# COMPUTE_CLUSTER0_CTL_CFG register map
Vendor: Texas Instruments
Peripheral module from a debugger description file (folder J7VCL).
Registers are 32-bit, read-write, reset 0x0 unless marked. A register's access mark holds for its fields unless they carry their own. Offsets are as the file gives them; lines under a group give offsets from that group; [hi:lo] are bit positions; {n}, {i} and the like mark numbered series; 'fields as' and 'values as' point back to an identical list; <NAME> marks a mode.

## COMPUTE_CLUSTER0_CTL_CFG (part 1 of 3)
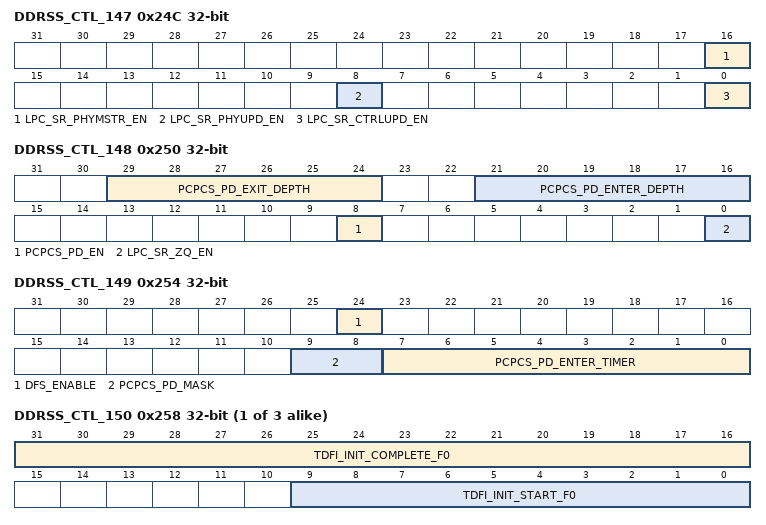
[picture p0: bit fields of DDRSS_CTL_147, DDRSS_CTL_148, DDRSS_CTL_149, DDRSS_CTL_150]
0x24C DDRSS_CTL_147
  [16] LPC_SR_PHYMSTR_EN — Enable LPC to execute a DFI PHY Master request on a self-refresh exit sequence.
  [8] LPC_SR_PHYUPD_EN — Enable LPC to execute a DFI PHY update on a self-refresh exit sequence.
  [0] LPC_SR_CTRLUPD_EN — Enable LPC to execute a DFI control update on a self-refresh exit sequence.
0x250 DDRSS_CTL_148
  [29:24] PCPCS_PD_EXIT_DEPTH — Defines the number of entries of the command queue that the PCPCS logic will consider for dynamic power-down exit decode.
  [21:16] PCPCS_PD_ENTER_DEPTH — Defines the number of entries of the command queue that the PCPCS logic will consider for dynamic power-down entry decode.
  [8] PCPCS_PD_EN — Enable dynamic PCPCS to allow chip selects to dynamically enter and exit power-down.
  [0] LPC_SR_ZQ_EN — Enable LPC to execute a ZQ calibration on a self-refresh exit sequence.
0x254 DDRSS_CTL_149
  [24] DFS_ENABLE — Enable hardware dynamic frequency scaling.
  [9:8] PCPCS_PD_MASK — Disables dynamic PCPCS power-down entry/exit for particular chip selects if the PCPCS_PD_EN parameter is set.
  [7:0] PCPCS_PD_ENTER_TIMER — Sets the delay used by dynamic PCPCS from when the decode logic determines that a chip select has no outstanding transactions to when the power-down entry command is issued.
{0x0+4i} DDRSS_CTL_{i} (i=150..152)
  [31:16] TDFI_INIT_COMPLETE_F{i-150} — Defines the DFI tINIT_COMPLETE timing parameter (in DFI clocks) for frequency copy {i-150}, the maximum cycles between a dfi_init_start de-assertion and a dfi_init_complete assertion from the PHY.
  [9:0] TDFI_INIT_START_F{i-150} — Defines the DFI tINIT_START timing parameter (in DFI clocks) for frequency copy {i-150}, the maximum number of cycles between a dfi_init_start assertion and a dfi_init_complete de-assertion from the PHY.
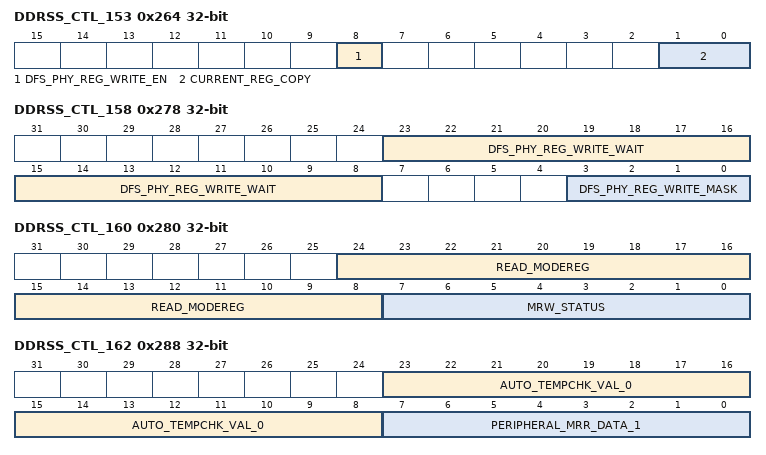
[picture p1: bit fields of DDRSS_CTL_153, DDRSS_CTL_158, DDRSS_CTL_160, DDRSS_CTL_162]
0x264 DDRSS_CTL_153 access per field
  [8] DFS_PHY_REG_WRITE_EN rw — Enable a register write to the PHY during a frequency change.
  [1:0] CURRENT_REG_COPY ro — Indicates the current copy of timing parameters that is in use by the controller.
0x268 DDRSS_CTL_154
  [31:0] DFS_PHY_REG_WRITE_ADDR — Register address which will be written during a frequency change.
{0x0+4i} DDRSS_CTL_{i} (i=155..157)
  [31:0] DFS_PHY_REG_WRITE_DATA_F{i-155} — Register data which will be written during a frequency change for frequency copy {i-155}.
0x278 DDRSS_CTL_158
  [23:8] DFS_PHY_REG_WRITE_WAIT — Defines the number of DFI PHY clocks that the controller will wait after issuing the register write to the PHY during a frequency change.
  [3:0] DFS_PHY_REG_WRITE_MASK — Register mask which will be written during a frequency change.
0x27C DDRSS_CTL_159
  [26:0] WRITE_MODEREG — Write memory mode register data to the DRAMs.
0x280 DDRSS_CTL_160 access per field
  [24:8] READ_MODEREG rw — Read the specified memory mode register from specified chip when start bit set.
  [7:0] MRW_STATUS ro — Write memory mode register status.
0x284 DDRSS_CTL_161 ro
  [31:0] PERIPHERAL_MRR_DATA_0 — Data and chip returned from memory mode register read requested by the READ_MODEREG parameter.
0x288 DDRSS_CTL_162 ro
  [23:8] AUTO_TEMPCHK_VAL_0 — MR4 data for all devices on chip 0 accessed by automatic MRR commands.
  [7:0] PERIPHERAL_MRR_DATA_1 — Data and chip returned from memory mode register read requested by the READ_MODEREG parameter.
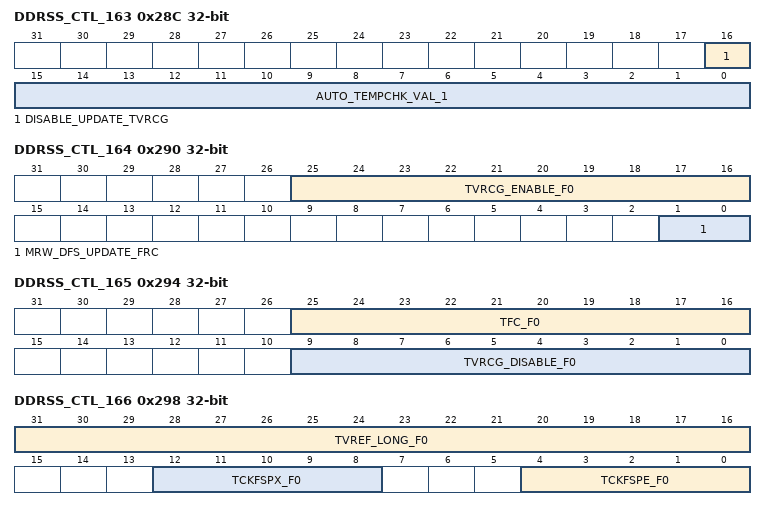
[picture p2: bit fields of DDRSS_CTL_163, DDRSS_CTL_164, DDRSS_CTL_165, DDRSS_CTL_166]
0x28C DDRSS_CTL_163 access per field
  [16] DISABLE_UPDATE_TVRCG rw — Bypass changing for TVRCG during a DFS operation.
  [15:0] AUTO_TEMPCHK_VAL_1 ro — MR4 data for all devices on chip 1 accessed by automatic MRR commands.
0x290 DDRSS_CTL_164
  [25:16] TVRCG_ENABLE_F0 — JEDEC TVRCG_ENABLE time.
  [1:0] MRW_DFS_UPDATE_FRC — Defines the frequency register set to use when doing a software MRW with WRITE_MODEREG bit (26).
0x294 DDRSS_CTL_165
  [25:16] TFC_F0 — JEDEC TFC, the frequency set point switching time.
  [9:0] TVRCG_DISABLE_F0 — JEDEC TVRCG_DISABLE time.
0x298 DDRSS_CTL_166
  [31:16] TVREF_LONG_F0 — JEDEC TVREF, design will always use the long value.
  [12:8] TCKFSPX_F0 — JEDEC TCKFSPX, the valid clock requirement before 1st valid command after FSP change.
  [4:0] TCKFSPE_F0 — JEDEC TCKFSPE, the valid clock requirement after entering SDP change.
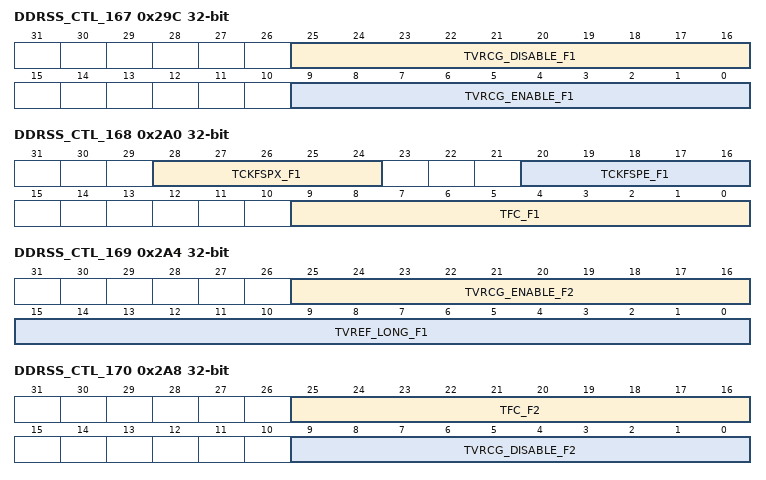
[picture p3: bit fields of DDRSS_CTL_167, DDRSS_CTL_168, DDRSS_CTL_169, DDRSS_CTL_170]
0x29C DDRSS_CTL_167
  [25:16] TVRCG_DISABLE_F1 — JEDEC TVRCG_DISABLE time.
  [9:0] TVRCG_ENABLE_F1 — JEDEC TVRCG_ENABLE time.
0x2A0 DDRSS_CTL_168
  [28:24] TCKFSPX_F1 — JEDEC TCKFSPX, the valid clock requirement before 1st valid command after FSP change.
  [20:16] TCKFSPE_F1 — JEDEC TCKFSPE, the valid clock requirement after entering SDP change.
  [9:0] TFC_F1 — JEDEC TFC, the frequency set point switching time.
0x2A4 DDRSS_CTL_169
  [25:16] TVRCG_ENABLE_F2 — JEDEC TVRCG_ENABLE time.
  [15:0] TVREF_LONG_F1 — JEDEC TVREF, design will always use the long value.
0x2A8 DDRSS_CTL_170
  [25:16] TFC_F2 — JEDEC TFC, the frequency set point switching time.
  [9:0] TVRCG_DISABLE_F2 — JEDEC TVRCG_DISABLE time.
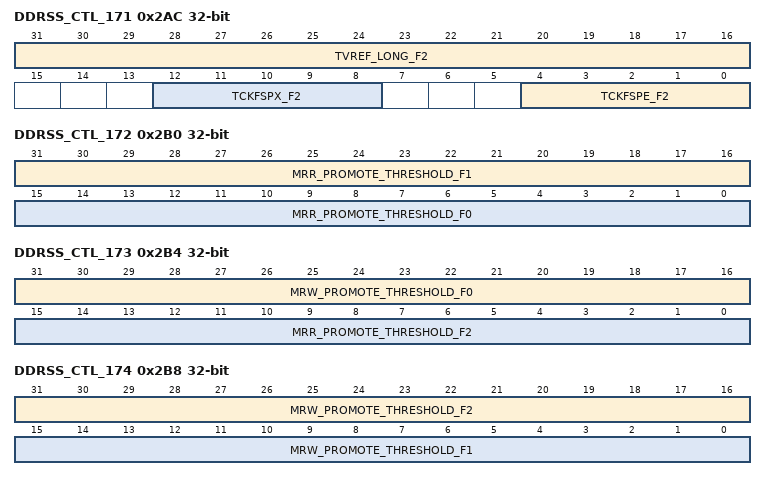
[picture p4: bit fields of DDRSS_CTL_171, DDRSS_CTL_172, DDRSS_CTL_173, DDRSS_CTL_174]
0x2AC DDRSS_CTL_171
  [31:16] TVREF_LONG_F2 — JEDEC TVREF, design will always use the long value.
  [12:8] TCKFSPX_F2 — JEDEC TCKFSPX, the valid clock requirement before 1st valid command after FSP change.
  [4:0] TCKFSPE_F2 — JEDEC TCKFSPE, the valid clock requirement after entering SDP change.
0x2B0 DDRSS_CTL_172
  [31:16] MRR_PROMOTE_THRESHOLD_F1 — MRR promotion number of long counts until the high priority request is asserted for frequency copy 1.
  [15:0] MRR_PROMOTE_THRESHOLD_F0 — MRR promotion number of long counts until the high priority request is asserted for frequency copy 0.
0x2B4 DDRSS_CTL_173
  [31:16] MRW_PROMOTE_THRESHOLD_F0 — MRW promotion number of long counts until the high priority request is asserted for frequency copy 0.
  [15:0] MRR_PROMOTE_THRESHOLD_F2 — MRR promotion number of long counts until the high priority request is asserted for frequency copy 2.
0x2B8 DDRSS_CTL_174
  [31:16] MRW_PROMOTE_THRESHOLD_F2 — MRW promotion number of long counts until the high priority request is asserted for frequency copy 2.
  [15:0] MRW_PROMOTE_THRESHOLD_F1 — MRW promotion number of long counts until the high priority request is asserted for frequency copy 1.
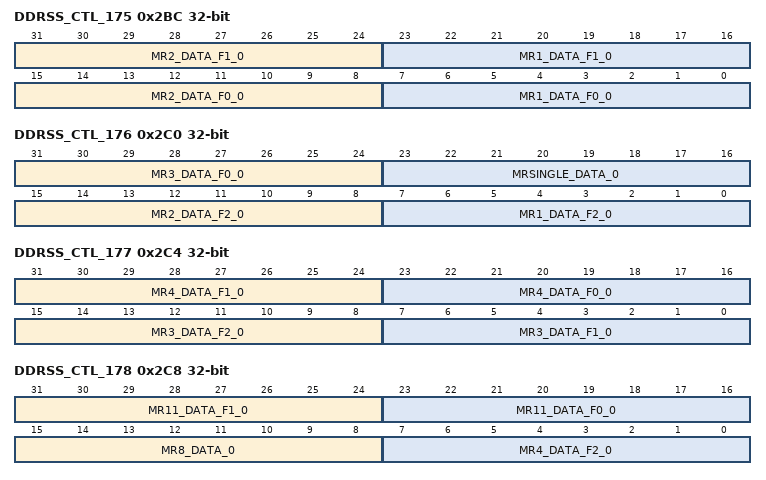
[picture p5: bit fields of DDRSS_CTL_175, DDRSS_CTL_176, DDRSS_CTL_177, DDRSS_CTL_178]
0x2BC DDRSS_CTL_175
  [31:24] MR2_DATA_F1_0 — Data to program into memory mode register 2 for chip select 0 for frequency copy 1.
  [23:16] MR1_DATA_F1_0 — Data to program into memory mode register 1 for chip select 0 for frequency copy 1.
  [15:8] MR2_DATA_F0_0 — Data to program into memory mode register 2 for chip select 0 for frequency copy 0.
  [7:0] MR1_DATA_F0_0 — Data to program into memory mode register 1 for chip select 0 for frequency copy 0.
0x2C0 DDRSS_CTL_176
  [31:24] MR3_DATA_F0_0 — Data to program into memory mode register 3 for chip select 0 for frequency copy 0.
  [23:16] MRSINGLE_DATA_0 — Data to program into memory mode register single write to chip select 0.
  [15:8] MR2_DATA_F2_0 — Data to program into memory mode register 2 for chip select 0 for frequency copy 2.
  [7:0] MR1_DATA_F2_0 — Data to program into memory mode register 1 for chip select 0 for frequency copy 2.
0x2C4 DDRSS_CTL_177
  [31:24] MR4_DATA_F1_0 — Data to program into memory mode register 4 for chip select 0 for frequency copy 1.
  [23:16] MR4_DATA_F0_0 — Data to program into memory mode register 4 for chip select 0 for frequency copy 0.
  [15:8] MR3_DATA_F2_0 — Data to program into memory mode register 3 for chip select 0 for frequency copy 2.
  [7:0] MR3_DATA_F1_0 — Data to program into memory mode register 3 for chip select 0 for frequency copy 1.
0x2C8 DDRSS_CTL_178 access per field
  [31:24] MR11_DATA_F1_0 rw — Data to program into memory mode register 11 for chip select 0 for frequency copy 1.
  [23:16] MR11_DATA_F0_0 rw — Data to program into memory mode register 11 for chip select 0 for frequency copy 0.
  [15:8] MR8_DATA_0 ro — Data read from MR8 for chip select 0.
  [7:0] MR4_DATA_F2_0 rw — Data to program into memory mode register 4 for chip select 0 for frequency copy 2.
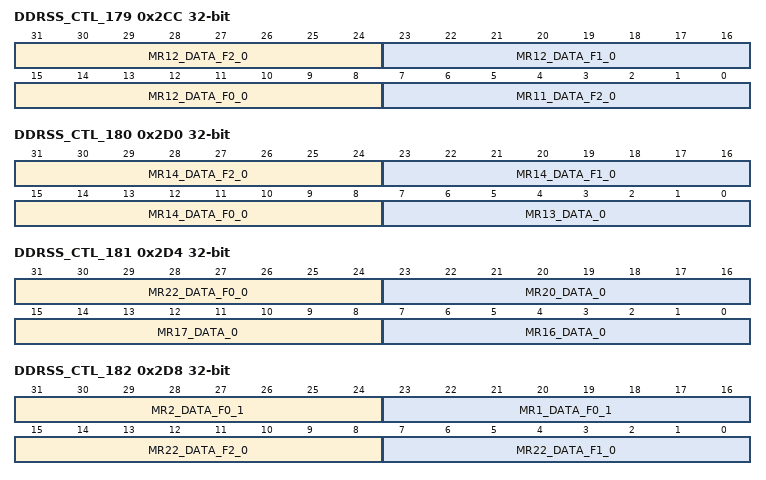
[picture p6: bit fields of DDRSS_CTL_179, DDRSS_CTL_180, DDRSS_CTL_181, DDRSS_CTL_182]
0x2CC DDRSS_CTL_179
  [31:24] MR12_DATA_F2_0 — Data to program into memory mode register 12 for chip select 0.
  [23:16] MR12_DATA_F1_0 — Data to program into memory mode register 12 for chip select 0.
  [15:8] MR12_DATA_F0_0 — Data to program into memory mode register 12 for chip select 0.
  [7:0] MR11_DATA_F2_0 — Data to program into memory mode register 11 for chip select 0 for frequency copy 2.
0x2D0 DDRSS_CTL_180
  [31:24] MR14_DATA_F2_0 — Data to program into memory mode register 14 for chip select 0.
  [23:16] MR14_DATA_F1_0 — Data to program into memory mode register 14 for chip select 0.
  [15:8] MR14_DATA_F0_0 — Data to program into memory mode register 14 for chip select 0.
  [7:0] MR13_DATA_0 — Data to program into memory mode register 13 for chip select 0.
0x2D4 DDRSS_CTL_181 access per field
  [31:24] MR22_DATA_F0_0 rw — Data to program into memory mode register 22 for chip select 0.
  [23:16] MR20_DATA_0 ro — Data read from MR20 for chip select 0.
  [15:8] MR17_DATA_0 rw — Data to program into memory mode register 17 for chip select 0.
  [7:0] MR16_DATA_0 rw — Data to program into memory mode register 16 for chip select 0.
0x2D8 DDRSS_CTL_182
  [31:24] MR2_DATA_F0_1 — Data to program into memory mode register 2 for chip select 1 for frequency copy 0.
  [23:16] MR1_DATA_F0_1 — Data to program into memory mode register 1 for chip select 1 for frequency copy 0.
  [15:8] MR22_DATA_F2_0 — Data to program into memory mode register 22 for chip select 0.
  [7:0] MR22_DATA_F1_0 — Data to program into memory mode register 22 for chip select 0.
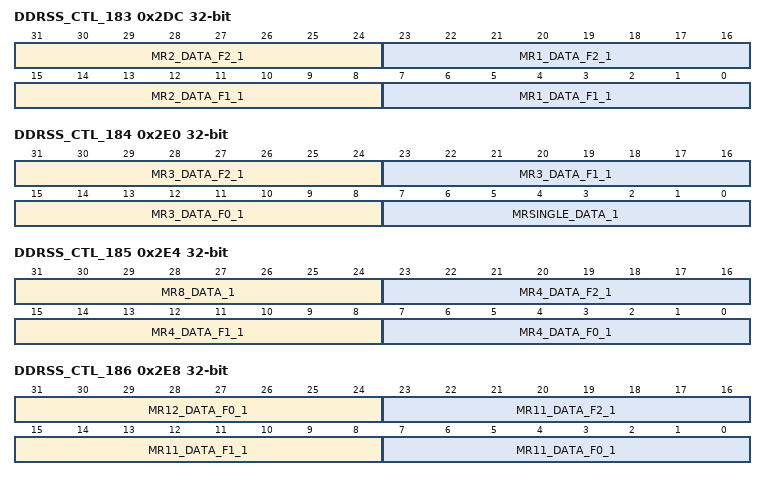
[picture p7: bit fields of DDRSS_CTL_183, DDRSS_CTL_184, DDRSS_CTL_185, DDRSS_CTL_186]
0x2DC DDRSS_CTL_183
  [31:24] MR2_DATA_F2_1 — Data to program into memory mode register 2 for chip select 1 for frequency copy 2.
  [23:16] MR1_DATA_F2_1 — Data to program into memory mode register 1 for chip select 1 for frequency copy 2.
  [15:8] MR2_DATA_F1_1 — Data to program into memory mode register 2 for chip select 1 for frequency copy 1.
  [7:0] MR1_DATA_F1_1 — Data to program into memory mode register 1 for chip select 1 for frequency copy 1.
0x2E0 DDRSS_CTL_184
  [31:24] MR3_DATA_F2_1 — Data to program into memory mode register 3 for chip select 1 for frequency copy 2.
  [23:16] MR3_DATA_F1_1 — Data to program into memory mode register 3 for chip select 1 for frequency copy 1.
  [15:8] MR3_DATA_F0_1 — Data to program into memory mode register 3 for chip select 1 for frequency copy 0.
  [7:0] MRSINGLE_DATA_1 — Data to program into memory mode register single write to chip select 1.
0x2E4 DDRSS_CTL_185 access per field
  [31:24] MR8_DATA_1 ro — Data read from MR8 for chip select 1.
  [23:16] MR4_DATA_F2_1 rw — Data to program into memory mode register 4 for chip select 1 for frequency copy 2.
  [15:8] MR4_DATA_F1_1 rw — Data to program into memory mode register 4 for chip select 1 for frequency copy 1.
  [7:0] MR4_DATA_F0_1 rw — Data to program into memory mode register 4 for chip select 1 for frequency copy 0.
0x2E8 DDRSS_CTL_186
  [31:24] MR12_DATA_F0_1 — Data to program into memory mode register 12 for chip select 1.
  [23:16] MR11_DATA_F2_1 — Data to program into memory mode register 11 for chip select 1 for frequency copy 2.
  [15:8] MR11_DATA_F1_1 — Data to program into memory mode register 11 for chip select 1 for frequency copy 1.
  [7:0] MR11_DATA_F0_1 — Data to program into memory mode register 11 for chip select 1 for frequency copy 0.
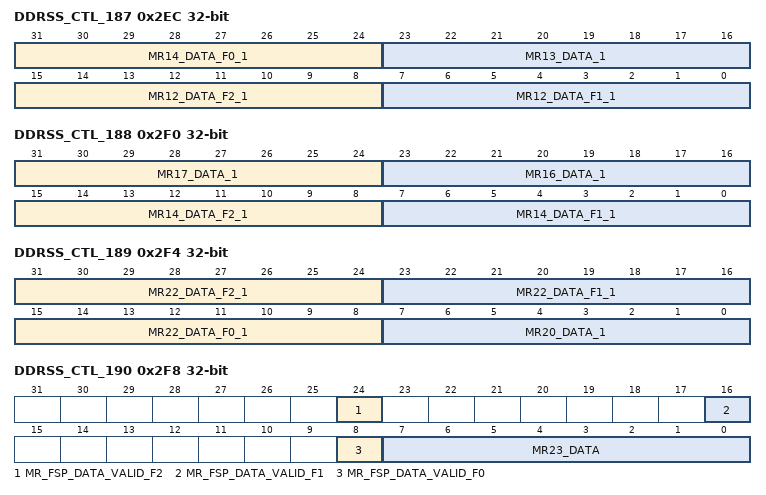
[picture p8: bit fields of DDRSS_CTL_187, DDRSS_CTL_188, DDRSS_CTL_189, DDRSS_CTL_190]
0x2EC DDRSS_CTL_187
  [31:24] MR14_DATA_F0_1 — Data to program into memory mode register 14 for chip select 1.
  [23:16] MR13_DATA_1 — Data to program into memory mode register 13 for chip select 1.
  [15:8] MR12_DATA_F2_1 — Data to program into memory mode register 12 for chip select 1.
  [7:0] MR12_DATA_F1_1 — Data to program into memory mode register 12 for chip select 1.
0x2F0 DDRSS_CTL_188
  [31:24] MR17_DATA_1 — Data to program into memory mode register 17 for chip select 1.
  [23:16] MR16_DATA_1 — Data to program into memory mode register 16 for chip select 1.
  [15:8] MR14_DATA_F2_1 — Data to program into memory mode register 14 for chip select 1.
  [7:0] MR14_DATA_F1_1 — Data to program into memory mode register 14 for chip select 1.
0x2F4 DDRSS_CTL_189 access per field
  [31:24] MR22_DATA_F2_1 rw — Data to program into memory mode register 22 for chip select 1.
  [23:16] MR22_DATA_F1_1 rw — Data to program into memory mode register 22 for chip select 1.
  [15:8] MR22_DATA_F0_1 rw — Data to program into memory mode register 22 for chip select 1.
  [7:0] MR20_DATA_1 ro — Data read from MR20 for chip select 1.
0x2F8 DDRSS_CTL_190
  [24] MR_FSP_DATA_VALID_F2 — Indicates that, at this frequency, memory was trained and the associated data has been loaded into the MRx_DATA parameter(s).
  [16] MR_FSP_DATA_VALID_F1 — Indicates that, at this frequency, memory was trained and the associated data has been loaded into the MRx_DATA parameter(s).
  [8] MR_FSP_DATA_VALID_F0 — Indicates that, at this frequency, memory was trained and the associated data has been loaded into the MRx_DATA parameter(s).
  [7:0] MR23_DATA — Data to program into memory mode register 23.
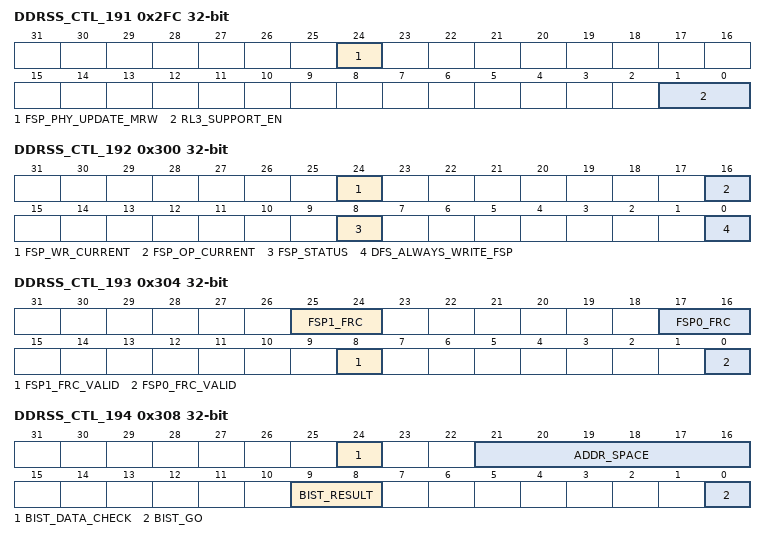
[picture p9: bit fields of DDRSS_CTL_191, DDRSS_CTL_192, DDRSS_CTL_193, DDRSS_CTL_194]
0x2FC DDRSS_CTL_191 access per field
  [24] FSP_PHY_UPDATE_MRW rw — Identifies the logic responsible for updating MR12 and MR14 in memory.
  [1:0] RL3_SUPPORT_EN ro — Indicates if RL3 is supported by a connected LPDDR3 memory.
0x300 DDRSS_CTL_192
  [24] FSP_WR_CURRENT — Reports which FSP set the memory will target with write commands.
  [16] FSP_OP_CURRENT — Reports which FSP set the memory is currently using.
  [8] FSP_STATUS — Indicates that a DFS event caused the FSP mode registers to be updated.
  [0] DFS_ALWAYS_WRITE_FSP — Forces all FSP mode registers to be written by the controller during a DFS event.
0x304 DDRSS_CTL_193
  [25:24] FSP1_FRC — Identifies which of the controller's frequency copy is associated with FSP1.
  [17:16] FSP0_FRC — Identifies which of the controller's frequency copy is associated with FSP0.
  [8] FSP1_FRC_VALID — Specifies whether the FSP set defined in the FSP1_FRC parameter reflects the frequency used to program the FSP1 registers.
  [0] FSP0_FRC_VALID — Specifies whether the FSP set defined in the FSP0_FRC parameter reflects the frequency used to program the FSP0 registers.
0x308 DDRSS_CTL_194 access per field
  [24] BIST_DATA_CHECK rw — Enable data checking with BIST operation.
  [21:16] ADDR_SPACE rw — Sets the number of address bits to check during BIST operation.
  [9:8] BIST_RESULT ro — BIST operation status (pass/fail).
  [0] BIST_GO wo — Initiate a BIST operation.
0x30C DDRSS_CTL_195
  [0] BIST_ADDR_CHECK — Enable address checking with BIST operation.
0x310 DDRSS_CTL_196
  [31:0] BIST_START_ADDRESS_0 — Start BIST checking at this address.
0x314 DDRSS_CTL_197
  [2:0] BIST_START_ADDRESS_1 — Start BIST checking at this address.
0x318 DDRSS_CTL_198
  [31:0] BIST_DATA_MASK_0 — Mask applied to data for BIST error checking.
0x31C DDRSS_CTL_199
  [31:0] BIST_DATA_MASK_1 — Mask applied to data for BIST error checking.
0x320 DDRSS_CTL_200
  [2:0] BIST_TEST_MODE — Sets the BIST test mode.
{0x0+4i} DDRSS_CTL_{i} (i=201..204)
  [31:0] BIST_DATA_PATTERN_{i-201} — Data pattern to be used when the BIST_TEST_MODE parameter is programmed to 1, 2, 3 or 4.
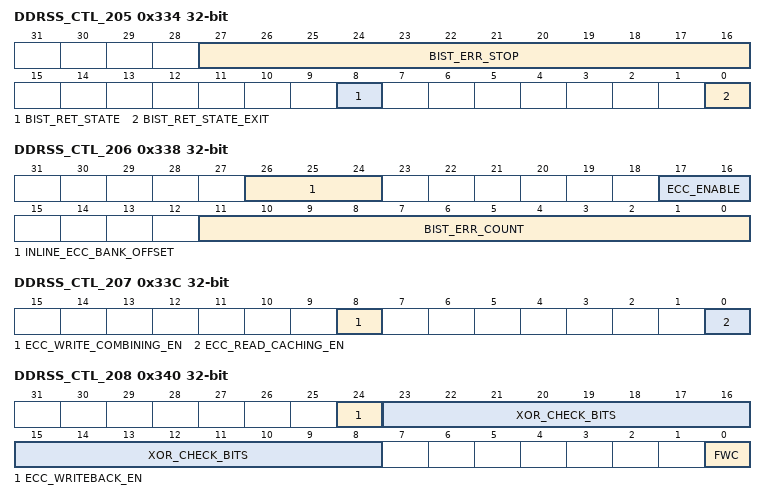
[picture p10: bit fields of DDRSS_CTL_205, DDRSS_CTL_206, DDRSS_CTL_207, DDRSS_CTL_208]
0x334 DDRSS_CTL_205 access per field
  [27:16] BIST_ERR_STOP rw — Defines the maximum number of error occurrences allowed prior to quitting when the BIST_TEST_MODE parameter is programmed to 1, 2 or 3.
  [8] BIST_RET_STATE ro — Indicates if BIST is in a retention wait state, used when the BIST_TEST_MODE parameter is programmed to 2 or 3.
  [0] BIST_RET_STATE_EXIT wo — Exit self-refresh or idle retention state, used when the BIST_TEST_MODE parameter is programmed to 2 or 3.
0x338 DDRSS_CTL_206 access per field — The ECC Engine block of the DDR controller is not supported.
  [26:24] INLINE_ECC_BANK_OFFSET rw — Inline ECC Bank Offset defines the bank shift between data and ECC commands associated with the same sequence
  [17:16] ECC_ENABLE rw — ECC error checking and correcting control register.
  [11:0] BIST_ERR_COUNT ro — Indicates the number of BIST errors found when the BIST_TEST_MODE parameter is programmed to 1, 2 or 3.
0x33C DDRSS_CTL_207
  [8] ECC_WRITE_COMBINING_EN — Allows ECC write data within a given ECC buffer to be combined across commands so that in certain cases where we see multiple ECC writes to the same ECC address, the controller may end up only issuing one final ECC write command to memory.
  [0] ECC_READ_CACHING_EN — Allows ECC read data already in one of the ECC buffers to be used when possible in place of issuing an ECC read command to memory.
0x340 DDRSS_CTL_208
  [24] ECC_WRITEBACK_EN — ECC writeback will occur on detection of single bit errors for reads.
  [23:8] XOR_CHECK_BITS — Value to xor with generated ECC codes for forced write check.
  [0] FWC — Force a write check.
0x344 DDRSS_CTL_209
  [0] ECC_DISABLE_W_UC_ERR — Controls auto-corruption of ECC when un-correctable errors occur in R/M/W operations.
0x348 DDRSS_CTL_210 ro
  [31:0] ECC_U_ADDR_0 — Address of uncorrectable ECC event.
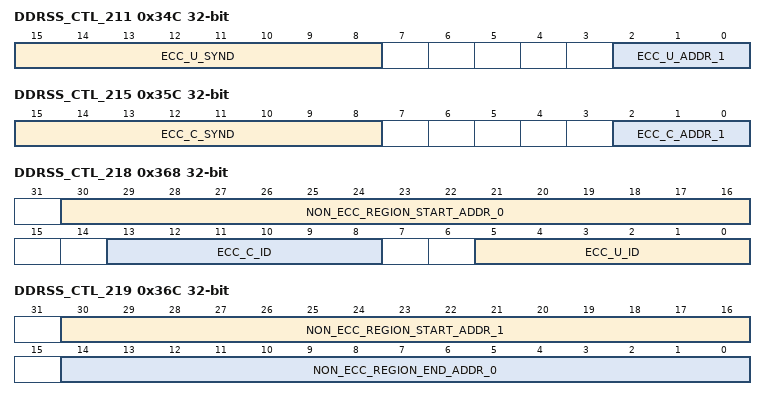
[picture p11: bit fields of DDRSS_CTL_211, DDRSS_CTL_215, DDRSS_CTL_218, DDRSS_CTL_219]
0x34C DDRSS_CTL_211 ro
  [15:8] ECC_U_SYND — Syndrome for uncorrectable ECC event.
  [2:0] ECC_U_ADDR_1 — Address of uncorrectable ECC event.
0x350 DDRSS_CTL_212 ro
  [31:0] ECC_U_DATA_0 — Data associated with uncorrectable ECC event.
0x354 DDRSS_CTL_213 ro
  [31:0] ECC_U_DATA_1 — Data associated with uncorrectable ECC event.
0x358 DDRSS_CTL_214 ro
  [31:0] ECC_C_ADDR_0 — Address of correctable ECC event.
0x35C DDRSS_CTL_215 ro
  [15:8] ECC_C_SYND — Syndrome for correctable ECC event.
  [2:0] ECC_C_ADDR_1 — Address of correctable ECC event.
0x360 DDRSS_CTL_216 ro
  [31:0] ECC_C_DATA_0 — Data associated with correctable ECC event.
0x364 DDRSS_CTL_217 ro
  [31:0] ECC_C_DATA_1 — Data associated with correctable ECC event.
0x368 DDRSS_CTL_218 access per field
  [30:16] NON_ECC_REGION_START_ADDR_0 rw — Set the base address of the soft-designated non-ECC region 0.
  [13:8] ECC_C_ID ro — Source ID associated with correctable ECC event.
  [5:0] ECC_U_ID ro — Source ID associated with the uncorrectable ECC event.
0x36C DDRSS_CTL_219
  [30:16] NON_ECC_REGION_START_ADDR_1 — Set the base address of the soft-designated non-ECC region 1.
  [14:0] NON_ECC_REGION_END_ADDR_0 — Set the base address of the soft-designated non-ECC region 0.
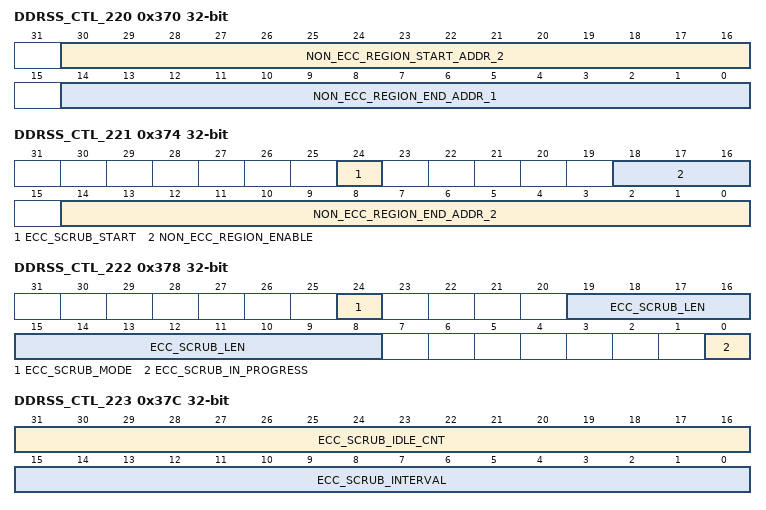
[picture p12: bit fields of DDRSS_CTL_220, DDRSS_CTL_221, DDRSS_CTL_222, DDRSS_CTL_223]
0x370 DDRSS_CTL_220
  [30:16] NON_ECC_REGION_START_ADDR_2 — Set the base address of the soft-designated non-ECC region 2.
  [14:0] NON_ECC_REGION_END_ADDR_1 — Set the base address of the soft-designated non-ECC region 1.
0x374 DDRSS_CTL_221 access per field
  [24] ECC_SCRUB_START wo — ECC scrubbing control.
  [18:16] NON_ECC_REGION_ENABLE rw — Enables each soft-designated non-ECC region.
  [14:0] NON_ECC_REGION_END_ADDR_2 rw — Set the base address of the soft-designated non-ECC region 2.
0x378 DDRSS_CTL_222 access per field
  [24] ECC_SCRUB_MODE rw — Defines how often ECC scrubbing operations will occur.
  [19:8] ECC_SCRUB_LEN rw — Defines the length of the ECC scrubbing read command that the controller will issue.
  [0] ECC_SCRUB_IN_PROGRESS ro — Reports the scrubbing operation status.
0x37C DDRSS_CTL_223
  [31:16] ECC_SCRUB_IDLE_CNT — The number of controller clock cycles that the scrubbing engine will wait in controller idle state before starting scrubbing operations.
  [15:0] ECC_SCRUB_INTERVAL — The minimum interval between two ECC scrubbing commands in number of controller clock cycles.
0x380 DDRSS_CTL_224
  [31:0] ECC_SCRUB_START_ADDR_0 — The starting address from where scrubbing operations will begin.
0x384 DDRSS_CTL_225
  [2:0] ECC_SCRUB_START_ADDR_1 — The starting address from where scrubbing operations will begin.
0x388 DDRSS_CTL_226
  [31:0] ECC_SCRUB_END_ADDR_0 — The end address where scrubbing operations will wrap around to the start address.
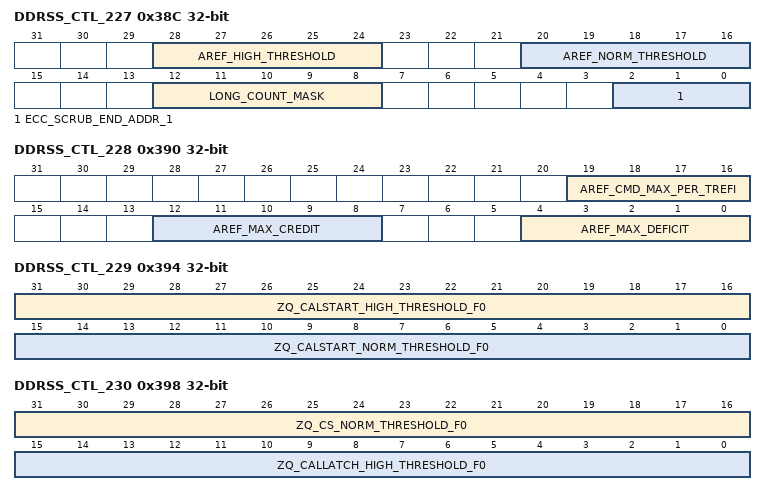
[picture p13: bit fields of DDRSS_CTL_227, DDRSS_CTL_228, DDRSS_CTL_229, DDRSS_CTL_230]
0x38C DDRSS_CTL_227
  [28:24] AREF_HIGH_THRESHOLD — AREF number of pending refreshes until the high priority request is asserted.
  [20:16] AREF_NORM_THRESHOLD — AREF number of pending refreshes until the normal priority request is asserted.
  [12:8] LONG_COUNT_MASK — Reduces the length of the long counter from 1024 cycles.
  [2:0] ECC_SCRUB_END_ADDR_1 — The end address where scrubbing operations will wrap around to the start address.
0x390 DDRSS_CTL_228
  [19:16] AREF_CMD_MAX_PER_TREFI — Sets the maximum number of auto-refreshes that will be executed in a TREFI period - both normal and high priority.
  [12:8] AREF_MAX_CREDIT — AREF number of posted refreshes until the maximum number of refresh credits has been reached.
  [4:0] AREF_MAX_DEFICIT — AREF number of pending refreshes until the maximum number of refreshes has been exceeded.
0x394 DDRSS_CTL_229
  [31:16] ZQ_CALSTART_HIGH_THRESHOLD_F0 — ZQ START number of long counts until the high priority request is asserted for frequency copy 0.
  [15:0] ZQ_CALSTART_NORM_THRESHOLD_F0 — ZQ START number of long counts until the normal priority request is asserted for frequency copy 0.
0x398 DDRSS_CTL_230
  [31:16] ZQ_CS_NORM_THRESHOLD_F0 — ZQ CS number of long counts until the normal priority request is asserted for frequency copy 0.
  [15:0] ZQ_CALLATCH_HIGH_THRESHOLD_F0 — ZQ LATCH number of long counts until the high priority request is asserted for frequency copy 0.
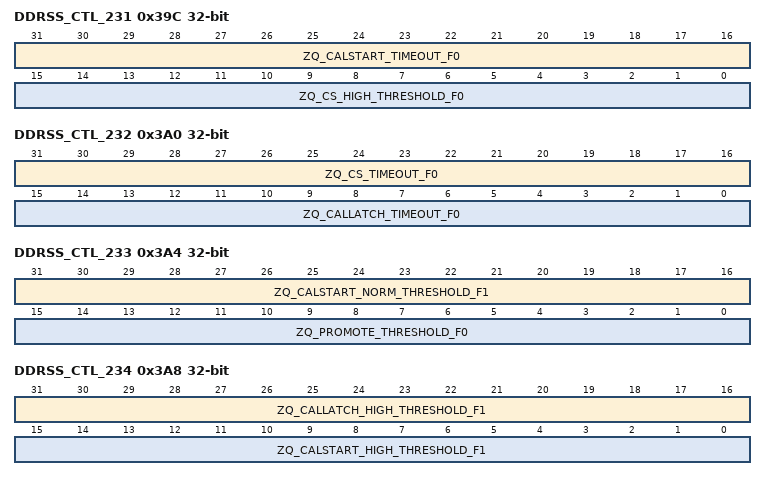
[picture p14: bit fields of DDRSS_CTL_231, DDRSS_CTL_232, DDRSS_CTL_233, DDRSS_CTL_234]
0x39C DDRSS_CTL_231
  [31:16] ZQ_CALSTART_TIMEOUT_F0 — ZQ START number of long counts until the timeout is asserted for frequency copy 0.
  [15:0] ZQ_CS_HIGH_THRESHOLD_F0 — ZQ CS number of long counts until the high priority request is asserted for frequency copy 0.
0x3A0 DDRSS_CTL_232
  [31:16] ZQ_CS_TIMEOUT_F0 — ZQ CS number of long counts until the timeout is asserted for frequency copy 0.
  [15:0] ZQ_CALLATCH_TIMEOUT_F0 — ZQ LATCH number of long counts until the timeout is asserted for frequency copy 0.
0x3A4 DDRSS_CTL_233
  [31:16] ZQ_CALSTART_NORM_THRESHOLD_F1 — ZQ START number of long counts until the normal priority request is asserted for frequency copy 1.
  [15:0] ZQ_PROMOTE_THRESHOLD_F0 — ZQ SW promotion number of long counts until the high priority request is asserted for frequency copy 0.
0x3A8 DDRSS_CTL_234
  [31:16] ZQ_CALLATCH_HIGH_THRESHOLD_F1 — ZQ LATCH number of long counts until the high priority request is asserted for frequency copy 1.
  [15:0] ZQ_CALSTART_HIGH_THRESHOLD_F1 — ZQ START number of long counts until the high priority request is asserted for frequency copy 1.
0x3AC DDRSS_CTL_235
  [31:16] ZQ_CS_HIGH_THRESHOLD_F1 — ZQ CS number of long counts until the high priority request is asserted for frequency copy 1.
  [15:0] ZQ_CS_NORM_THRESHOLD_F1 — ZQ CS number of long counts until the normal priority request is asserted for frequency copy 1.
0x3B0 DDRSS_CTL_236
  [31:16] ZQ_CALLATCH_TIMEOUT_F1 — ZQ LATCH number of long counts until the timeout is asserted for frequency copy 1.
  [15:0] ZQ_CALSTART_TIMEOUT_F1 — ZQ START number of long counts until the timeout is asserted for frequency copy 1.
0x3B4 DDRSS_CTL_237
  [31:16] ZQ_PROMOTE_THRESHOLD_F1 — ZQ SW promotion number of long counts until the high priority request is asserted for frequency copy 1.
  [15:0] ZQ_CS_TIMEOUT_F1 — ZQ CS number of long counts until the timeout is asserted for frequency copy 1.
0x3B8 DDRSS_CTL_238
  [31:16] ZQ_CALSTART_HIGH_THRESHOLD_F2 — ZQ START number of long counts until the high priority request is asserted for frequency copy 2.
  [15:0] ZQ_CALSTART_NORM_THRESHOLD_F2 — ZQ START number of long counts until the normal priority request is asserted for frequency copy 2.
0x3BC DDRSS_CTL_239
  [31:16] ZQ_CS_NORM_THRESHOLD_F2 — ZQ CS number of long counts until the normal priority request is asserted for frequency copy 2.
  [15:0] ZQ_CALLATCH_HIGH_THRESHOLD_F2 — ZQ LATCH number of long counts until the high priority request is asserted for frequency copy 2.
0x3C0 DDRSS_CTL_240
  [31:16] ZQ_CALSTART_TIMEOUT_F2 — ZQ START number of long counts until the timeout is asserted for frequency copy 2.
  [15:0] ZQ_CS_HIGH_THRESHOLD_F2 — ZQ CS number of long counts until the high priority request is asserted for frequency copy 2.
0x3C4 DDRSS_CTL_241
  [31:16] ZQ_CS_TIMEOUT_F2 — ZQ CS number of long counts until the timeout is asserted for frequency copy 2.
  [15:0] ZQ_CALLATCH_TIMEOUT_F2 — ZQ LATCH number of long counts until the timeout is asserted for frequency copy 2.
0x3C8 DDRSS_CTL_242
  [15:0] ZQ_PROMOTE_THRESHOLD_F2 — ZQ SW promotion number of long counts until the high priority request is asserted for frequency copy 2.
0x3CC DDRSS_CTL_243
  [31:16] WATCHDOG_THRESHOLD_BUS_ARB_F0 — When watchdog's counter reaches this threshold, it will assert an error when using frequency copy 0.
  [15:0] WATCHDOG_THRESHOLD_TASK_ARB_F0 — When watchdog's counter reaches this threshold, it will assert an error when using frequency copy 0.
0x3D0 DDRSS_CTL_244
  [31:16] WATCHDOG_THRESHOLD_SPLIT_F0 — When watchdog's counter reaches this threshold, it will assert an error when using frequency copy 0.
  [15:0] WATCHDOG_THRESHOLD_PORT0_CMD_ARB_F0 — When watchdog's counter reaches this threshold, it will assert an error when using frequency copy 0.
0x3D4 DDRSS_CTL_245
  [31:16] WATCHDOG_THRESHOLD_PORT_TO_STRATEGY_F0 — When watchdog's counter reaches this threshold, it will assert an error when using frequency copy 0.
  [15:0] WATCHDOG_THRESHOLD_STRATEGY_F0 — When watchdog's counter reaches this threshold, it will assert an error when using frequency copy 0.
0x3D8 DDRSS_CTL_246
  [31:16] WATCHDOG_THRESHOLD_WRITE_DATA_FIFO_F0 — When watchdog's counter reaches this threshold, it will assert an error when using frequency copy 0.
  [15:0] WATCHDOG_THRESHOLD_READ_DATA_FIFO0_F0 — When watchdog's counter reaches this threshold, it will assert an error when using frequency copy 0.
0x3DC DDRSS_CTL_247
  [31:16] WATCHDOG_THRESHOLD_BUS_ARB_F1 — When watchdog's counter reaches this threshold, it will assert an error when using frequency copy 1.
  [15:0] WATCHDOG_THRESHOLD_TASK_ARB_F1 — When watchdog's counter reaches this threshold, it will assert an error when using frequency copy 1.
0x3E0 DDRSS_CTL_248
  [31:16] WATCHDOG_THRESHOLD_SPLIT_F1 — When watchdog's counter reaches this threshold, it will assert an error when using frequency copy 1.
  [15:0] WATCHDOG_THRESHOLD_PORT0_CMD_ARB_F1 — When watchdog's counter reaches this threshold, it will assert an error when using frequency copy 1.
0x3E4 DDRSS_CTL_249
  [31:16] WATCHDOG_THRESHOLD_PORT_TO_STRATEGY_F1 — When watchdog's counter reaches this threshold, it will assert an error when using frequency copy 1.
  [15:0] WATCHDOG_THRESHOLD_STRATEGY_F1 — When watchdog's counter reaches this threshold, it will assert an error when using frequency copy 1.
0x3E8 DDRSS_CTL_250
  [31:16] WATCHDOG_THRESHOLD_WRITE_DATA_FIFO_F1 — When watchdog's counter reaches this threshold, it will assert an error when using frequency copy 1.
  [15:0] WATCHDOG_THRESHOLD_READ_DATA_FIFO0_F1 — When watchdog's counter reaches this threshold, it will assert an error when using frequency copy 1.
0x3EC DDRSS_CTL_251
  [31:16] WATCHDOG_THRESHOLD_BUS_ARB_F2 — When watchdog's counter reaches this threshold, it will assert an error when using frequency copy 2.
  [15:0] WATCHDOG_THRESHOLD_TASK_ARB_F2 — When watchdog's counter reaches this threshold, it will assert an error when using frequency copy 2.
0x3F0 DDRSS_CTL_252
  [31:16] WATCHDOG_THRESHOLD_SPLIT_F2 — When watchdog's counter reaches this threshold, it will assert an error when using frequency copy 2.
  [15:0] WATCHDOG_THRESHOLD_PORT0_CMD_ARB_F2 — When watchdog's counter reaches this threshold, it will assert an error when using frequency copy 2.
0x3F4 DDRSS_CTL_253
  [31:16] WATCHDOG_THRESHOLD_PORT_TO_STRATEGY_F2 — When watchdog's counter reaches this threshold, it will assert an error when using frequency copy 2.
  [15:0] WATCHDOG_THRESHOLD_STRATEGY_F2 — When watchdog's counter reaches this threshold, it will assert an error when using frequency copy 2.
0x3F8 DDRSS_CTL_254
  [31:16] WATCHDOG_THRESHOLD_WRITE_DATA_FIFO_F2 — When watchdog's counter reaches this threshold, it will assert an error when using frequency copy 2.
  [15:0] WATCHDOG_THRESHOLD_READ_DATA_FIFO0_F2 — When watchdog's counter reaches this threshold, it will assert an error when using frequency copy 2.
0x3FC DDRSS_CTL_255 access per field
  [15:8] WATCHDOG_DIAGNOSTIC_MODE rw — Used to test watchdog timers or to force a failure.
  [7:0] WATCHDOG_RELOAD wo — Forces reload to assert on all watchdog timers, effectively restarting all watchdog counters and clearing any existing watchdog error assertions.
0x400 DDRSS_CTL_256 ro
  [19:0] TIMEOUT_TIMER_LOG — Reflects which timers experienced a timeout error (or had an uncleared error) when the timeout interrupt fired.
0x404 DDRSS_CTL_257
  [27:16] ZQCL_F0 — Number of cycles needed for a ZQCL command for frequency copy 0.
  [11:0] ZQINIT_F0 — Number of cycles needed for a ZQINIT command for frequency copy 0.
0x408 DDRSS_CTL_258
  [27:16] TZQCAL_F0 — Holds the DRAM ZQCAL value for frequency copy 0 in cycles.
  [11:0] ZQCS_F0 — Number of cycles needed for a ZQCS command for frequency copy 0.
0x40C DDRSS_CTL_259
  [19:8] ZQINIT_F1 — Number of cycles needed for a ZQINIT command for frequency copy 1.
  [6:0] TZQLAT_F0 — Holds the DRAM ZQLAT value for frequency copy 0 in cycles.
0x410 DDRSS_CTL_260
  [27:16] ZQCS_F1 — Number of cycles needed for a ZQCS command for frequency copy 1.
  [11:0] ZQCL_F1 — Number of cycles needed for a ZQCL command for frequency copy 1.
0x414 DDRSS_CTL_261
  [22:16] TZQLAT_F1 — Holds the DRAM ZQLAT value for frequency copy 1 in cycles.
  [11:0] TZQCAL_F1 — Holds the DRAM ZQCAL value for frequency copy 1 in cycles.
0x418 DDRSS_CTL_262
  [27:16] ZQCL_F2 — Number of cycles needed for a ZQCL command for frequency copy 2.
  [11:0] ZQINIT_F2 — Number of cycles needed for a ZQINIT command for frequency copy 2.
0x41C DDRSS_CTL_263
  [27:16] TZQCAL_F2 — Holds the DRAM ZQCAL value for frequency copy 2 in cycles.
  [11:0] ZQCS_F2 — Number of cycles needed for a ZQCS command for frequency copy 2.
0x420 DDRSS_CTL_264 access per field
  [24] ZQ_REQ_PENDING ro — Indicates that a ZQ command is currently in progress or waiting to run.
  [19:16] ZQ_REQ wo — User request to initiate a ZQ calibration.
  [9:8] ZQ_SW_REQ_START_LATCH_MAP rw — Specifies which chip selects will simultaneously receive a ZQ start or latch command once the ZQ_REQ parameter is written with a ZQ Start or ZQ Latch command.
  [6:0] TZQLAT_F2 rw — Holds the DRAM ZQLAT value for frequency copy 2 in cycles.
0x424 DDRSS_CTL_265
  [27:16] ZQRESET_F1 — Number of cycles needed for a ZQRESET command for frequency copy 1.
  [11:0] ZQRESET_F0 — Number of cycles needed for a ZQRESET command for frequency copy 0.
0x428 DDRSS_CTL_266
  [24] ZQCS_ROTATE — For non-LPDDR4 memories, selects whether a ZQCS command will calibrate just one chip select or all chip selects.
  [16] NO_ZQ_INIT — Disable ZQ operations during initialization.
  [11:0] ZQRESET_F2 — Number of cycles needed for a ZQRESET command for frequency copy 2.
0x42C DDRSS_CTL_267
  [25:24] ZQ_CAL_LATCH_MAP_1 — Defines which chip select(s) will receive ZQ calibration latch commands simultaneously on iteration 1 of the ZQ LATCH initialization and periodic command sequences.
  [17:16] ZQ_CAL_START_MAP_1 — Defines which chip select(s) will receive ZQ calibration start commands simultaneously on iteration 1 of the ZQ START initialization and periodic command sequences.
  [9:8] ZQ_CAL_LATCH_MAP_0 — Defines which chip select(s) will receive ZQ calibration latch commands simultaneously on iteration 0 of the ZQ LATCH initialization and periodic command sequences.
  [1:0] ZQ_CAL_START_MAP_0 — Defines which chip select(s) will receive ZQ calibration start commands simultaneously on iteration 0 of the ZQ START initialization and periodic command sequences.
0x430 DDRSS_CTL_268
  [26:24] ROW_DIFF_1 — Difference between number of address pins available and number being used for chip select 1.
  [18:16] ROW_DIFF_0 — Difference between number of address pins available and number being used for chip select 0.
  [9:8] BANK_DIFF_1 — Encoded number of banks on the DRAM for chip select 1.
  [1:0] BANK_DIFF_0 — Encoded number of banks on the DRAM for chip select 0.
0x434 DDRSS_CTL_269
  [31:16] CS_VAL_LOWER_0 — Lower bound address for chip select 0.
  [11:8] COL_DIFF_1 — Difference between number of column pins available and number being used for chip select 1.
  [3:0] COL_DIFF_0 — Difference between number of column pins available and number being used for chip select 0.
0x438 DDRSS_CTL_270
  [18:16] ROW_START_VAL_0 — Row start value for chip select 0.
  [15:0] CS_VAL_UPPER_0 — Upper bound address for chip select 0.
0x43C DDRSS_CTL_271
  [31:16] CS_VAL_UPPER_1 — Upper bound address for chip select 1.
  [15:0] CS_VAL_LOWER_1 — Lower bound address for chip select 1.
0x440 DDRSS_CTL_272
  [31:16] CS_MSK_0 — Mask applied to the address decode for chip select 0.
  [9:8] CS_MAP_NON_POW2 — Defines which chip selects are non-power-of-2 memory sizes.
  [2:0] ROW_START_VAL_1 — Row start value for chip select 1.
0x444 DDRSS_CTL_273
  [16] CS_LOWER_ADDR_EN — Enables moving the CS field to lower in the address map.
  [15:0] CS_MSK_1 — Mask applied to the address decode for chip select 1.
0x448 DDRSS_CTL_274 reset 0xA00
  [31:24] COMMAND_AGE_COUNT — Initial value of individual command aging counters for command aging.
  [23:16] AGE_COUNT — Initial value of master aging-rate counter for command aging.
  [12:8] APREBIT — Location of the auto pre-charge bit in the DRAM address.
0x44C DDRSS_CTL_275
  [24] PLACEMENT_EN — Enable placement logic for command queue.
  [16] BANK_SPLIT_EN — Enable bank splitting as a rule for command queue placement.
  [8] ADDR_COLLISION_MPM_DIS — Disable address collision detection extension using micro page mask for command queue placement and selection.
  [0] ADDR_CMP_EN — Enable address collision detection as a rule for command queue placement.
0x450 DDRSS_CTL_276
  [24] CS_SAME_EN — Enable chip select grouping when read/write grouping as a rule for command queue placement.
  [16] RW_SAME_PAGE_EN — Enable page grouping when read/write grouping as a rule for command queue placement.
  [8] RW_SAME_EN — Enable read/write grouping as a rule for command queue placement.
  [0] PRIORITY_EN — Enable priority as a rule for command queue placement.
0x454 DDRSS_CTL_277
  [24] SWAP_EN — Enable command swapping logic in execution unit.
  [20:16] NUM_Q_ENTRIES_ACT_DISABLE — Number of queue entries in which ACT requests will be disabled.
  [9:8] DISABLE_RW_GROUP_W_BNK_CONFLICT — Disables placement to read/write group when grouping creates a bank collision.
  [0] W2R_SPLIT_EN — Enable splitting of commands to the same chip select from a write to a read command as a rule for command queue placement.
0x458 DDRSS_CTL_278
  [24] REDUC — Enable the half datapath feature of the controller.
  [17:16] CS_MAP — Defines which chip selects are active.
  [9:8] INHIBIT_DRAM_CMD — Inhibit command types from being executed from the command queue.
  [0] DISABLE_RD_INTERLEAVE — Disable read data interleaving for commands from the same port, regardless of the requestor ID.
0x45C DDRSS_CTL_279
  [17:0] FAULT_FIFO_PROTECTION_EN — Enables fault fifo protection features.
0x460 DDRSS_CTL_280 ro
  [17:0] FAULT_FIFO_PROTECTION_STATUS — Status of fault fifo protection modules.
0x464 DDRSS_CTL_281
  [24] WRITE_ADDR_CHAN_PARITY_EN — Enables parity checking on the AXI write command (address) channel.
  [17:0] FAULT_FIFO_PROTECTION_INJECTION_EN — Triggers error injection for fault fifo protection modules.
0x468 DDRSS_CTL_282
  [24] READ_DATA_CHAN_PARITY_EN — Enables parity checking on the AXI read data channel.
  [16] READ_ADDR_CHAN_PARITY_EN — Enables parity checking on the AXI read command (address) channel.
  [8] WRITE_RESP_CHAN_PARITY_EN — Enables parity checking on the AXI write response channel.
  [1:0] WRITE_DATA_CHAN_PARITY_EN — Enables parity checking on the AXI write data channel.
0x46C DDRSS_CTL_283
  [24] READ_PARITY_ERR_RRESP_EN — Enables AXI ERROR responses on the AXI read data channel for any parity errors that occurred on the read command (address) channel.
  [16] WRITE_PARITY_ERR_BRESP_EN — Enables AXI ERROR responses on the AXI write response channel for any parity errors that occured on either the write command (address) or write data channels.
0x470 DDRSS_CTL_284
  [24] READ_ADDR_CHAN_TRIGGER_PARITY_EN — Triggers a parity error on the AXI read command (address) channel.
  [16] WRITE_RESP_CHAN_CORRUPT_PARITY_EN — Corrupts the parity on the AXI write response channel.
  [8] WRITE_DATA_CHAN_TRIGGER_PARITY_EN — Triggers a parity error on the AXI write data channel.
  [0] WRITE_ADDR_CHAN_TRIGGER_PARITY_EN — Triggers a parity error on the AXI write command (address) channel.
0x474 DDRSS_CTL_285
  [24] ENHANCED_PARITY_PROTECTION_EN — Enable byte parity implementation on addr/data channels.
  [16] WRITE_PARITY_ERR_CORRUPT_ECC_EN — Enables corruption of ECC code if an AXI parity error is detected.
  [8] ECC_AXI_ERROR_RESPONSE_INHIBIT — Inhibits AXI ERROR responses when an ECC error occurs on the AXI read data channel.
  [0] READ_DATA_CHAN_CORRUPT_PARITY_EN — Corrupts the parity on the AXI read data channel.
0x478 DDRSS_CTL_286
  [27:24] DEVICE2_BYTE0_CS0 — Defines the byte location of byte0 in the memory datapath for device 2 on chip 0.
  [19:16] DEVICE1_BYTE0_CS0 — Defines the byte location of byte0 in the memory datapath for device 1 on chip 0.
  [11:8] DEVICE0_BYTE0_CS0 — Defines the byte location of byte0 in the memory datapath for device 0 on chip 0.
  [2:0] MEMDATA_RATIO_0 — Defines the ratio of the DRAM device size on chip select 0 to the memory data width.
0x47C DDRSS_CTL_287
  [27:24] DEVICE1_BYTE0_CS1 — Defines the byte location of byte0 in the memory datapath for device 1 on chip 1.
  [19:16] DEVICE0_BYTE0_CS1 — Defines the byte location of byte0 in the memory datapath for device 0 on chip 1.
  [10:8] MEMDATA_RATIO_1 — Defines the ratio of the DRAM device size on chip select 1 to the memory data width.
  [3:0] DEVICE3_BYTE0_CS0 — Defines the byte location of byte0 in the memory datapath for device 3 on chip 0.
